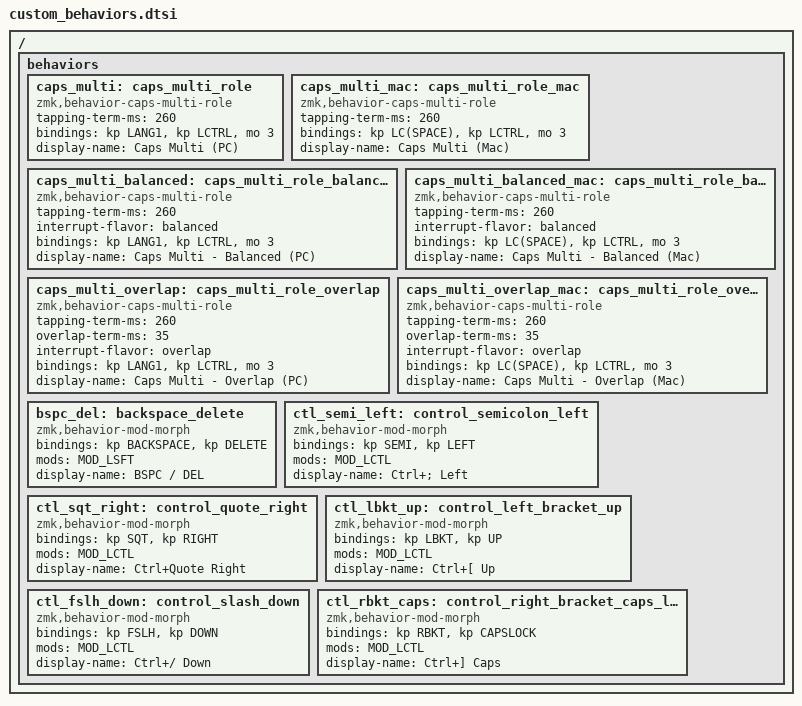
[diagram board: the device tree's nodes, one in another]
/*
 * SPDX-License-Identifier: MIT
 *
 * Personal ZMK Studio behaviors for the Tofu60 BLE 3.0.
 *
 * Do not add /omit-if-no-ref/ to these behaviors.
 * They must remain available in ZMK Studio even when the stock keymap
 * does not reference them.
 */

/ {
    behaviors {
        /*
         * Do not add /omit-if-no-ref/ here. This behavior must remain
         * selectable in Studio even if a future stock keymap stops using it.
         */
        caps_multi: caps_multi_role {
            compatible = "zmk,behavior-caps-multi-role";
            #binding-cells = <0>;
            tapping-term-ms = <260>;
            bindings = <&kp LANG1>, <&kp LCTRL>, <&mo 3>;
            display-name = "Caps Multi (PC)";
        };

        caps_multi_mac: caps_multi_role_mac {
            compatible = "zmk,behavior-caps-multi-role";
            #binding-cells = <0>;
            tapping-term-ms = <260>;
            bindings = <&kp LC(SPACE)>, <&kp LCTRL>, <&mo 3>;
            display-name = "Caps Multi (Mac)";
        };

        caps_multi_balanced: caps_multi_role_balanced {
            compatible = "zmk,behavior-caps-multi-role";
            #binding-cells = <0>;
            tapping-term-ms = <260>;
            interrupt-flavor = "balanced";
            bindings = <&kp LANG1>, <&kp LCTRL>, <&mo 3>;
            display-name = "Caps Multi - Balanced (PC)";
        };

        caps_multi_balanced_mac: caps_multi_role_balanced_mac {
            compatible = "zmk,behavior-caps-multi-role";
            #binding-cells = <0>;
            tapping-term-ms = <260>;
            interrupt-flavor = "balanced";
            bindings = <&kp LC(SPACE)>, <&kp LCTRL>, <&mo 3>;
            display-name = "Caps Multi - Balanced (Mac)";
        };

        caps_multi_overlap: caps_multi_role_overlap {
            compatible = "zmk,behavior-caps-multi-role";
            #binding-cells = <0>;
            tapping-term-ms = <260>;
            overlap-term-ms = <35>;
            interrupt-flavor = "overlap";
            bindings = <&kp LANG1>, <&kp LCTRL>, <&mo 3>;
            display-name = "Caps Multi - Overlap (PC)";
        };

        caps_multi_overlap_mac: caps_multi_role_overlap_mac {
            compatible = "zmk,behavior-caps-multi-role";
            #binding-cells = <0>;
            tapping-term-ms = <260>;
            overlap-term-ms = <35>;
            interrupt-flavor = "overlap";
            bindings = <&kp LC(SPACE)>, <&kp LCTRL>, <&mo 3>;
            display-name = "Caps Multi - Overlap (Mac)";
        };

        bspc_del: backspace_delete {
            compatible = "zmk,behavior-mod-morph";
            #binding-cells = <0>;
            bindings = <&kp BACKSPACE>, <&kp DELETE>;
            mods = <MOD_LSFT>;
            display-name = "BSPC / DEL";
        };

        ctl_semi_left: control_semicolon_left {
            compatible = "zmk,behavior-mod-morph";
            #binding-cells = <0>;
            bindings = <&kp SEMI>, <&kp LEFT>;
            mods = <MOD_LCTL>;
            display-name = "Ctrl+; Left";
        };

        ctl_sqt_right: control_quote_right {
            compatible = "zmk,behavior-mod-morph";
            #binding-cells = <0>;
            bindings = <&kp SQT>, <&kp RIGHT>;
            mods = <MOD_LCTL>;
            display-name = "Ctrl+Quote Right";
        };

        ctl_lbkt_up: control_left_bracket_up {
            compatible = "zmk,behavior-mod-morph";
            #binding-cells = <0>;
            bindings = <&kp LBKT>, <&kp UP>;
            mods = <MOD_LCTL>;
            display-name = "Ctrl+[ Up";
        };

        ctl_fslh_down: control_slash_down {
            compatible = "zmk,behavior-mod-morph";
            #binding-cells = <0>;
            bindings = <&kp FSLH>, <&kp DOWN>;
            mods = <MOD_LCTL>;
            display-name = "Ctrl+/ Down";
        };

        ctl_rbkt_caps: control_right_bracket_caps_lock {
            compatible = "zmk,behavior-mod-morph";
            #binding-cells = <0>;
            bindings = <&kp RBKT>, <&kp CAPSLOCK>;
            mods = <MOD_LCTL>;
            display-name = "Ctrl+] Caps";
        };
    };
};
